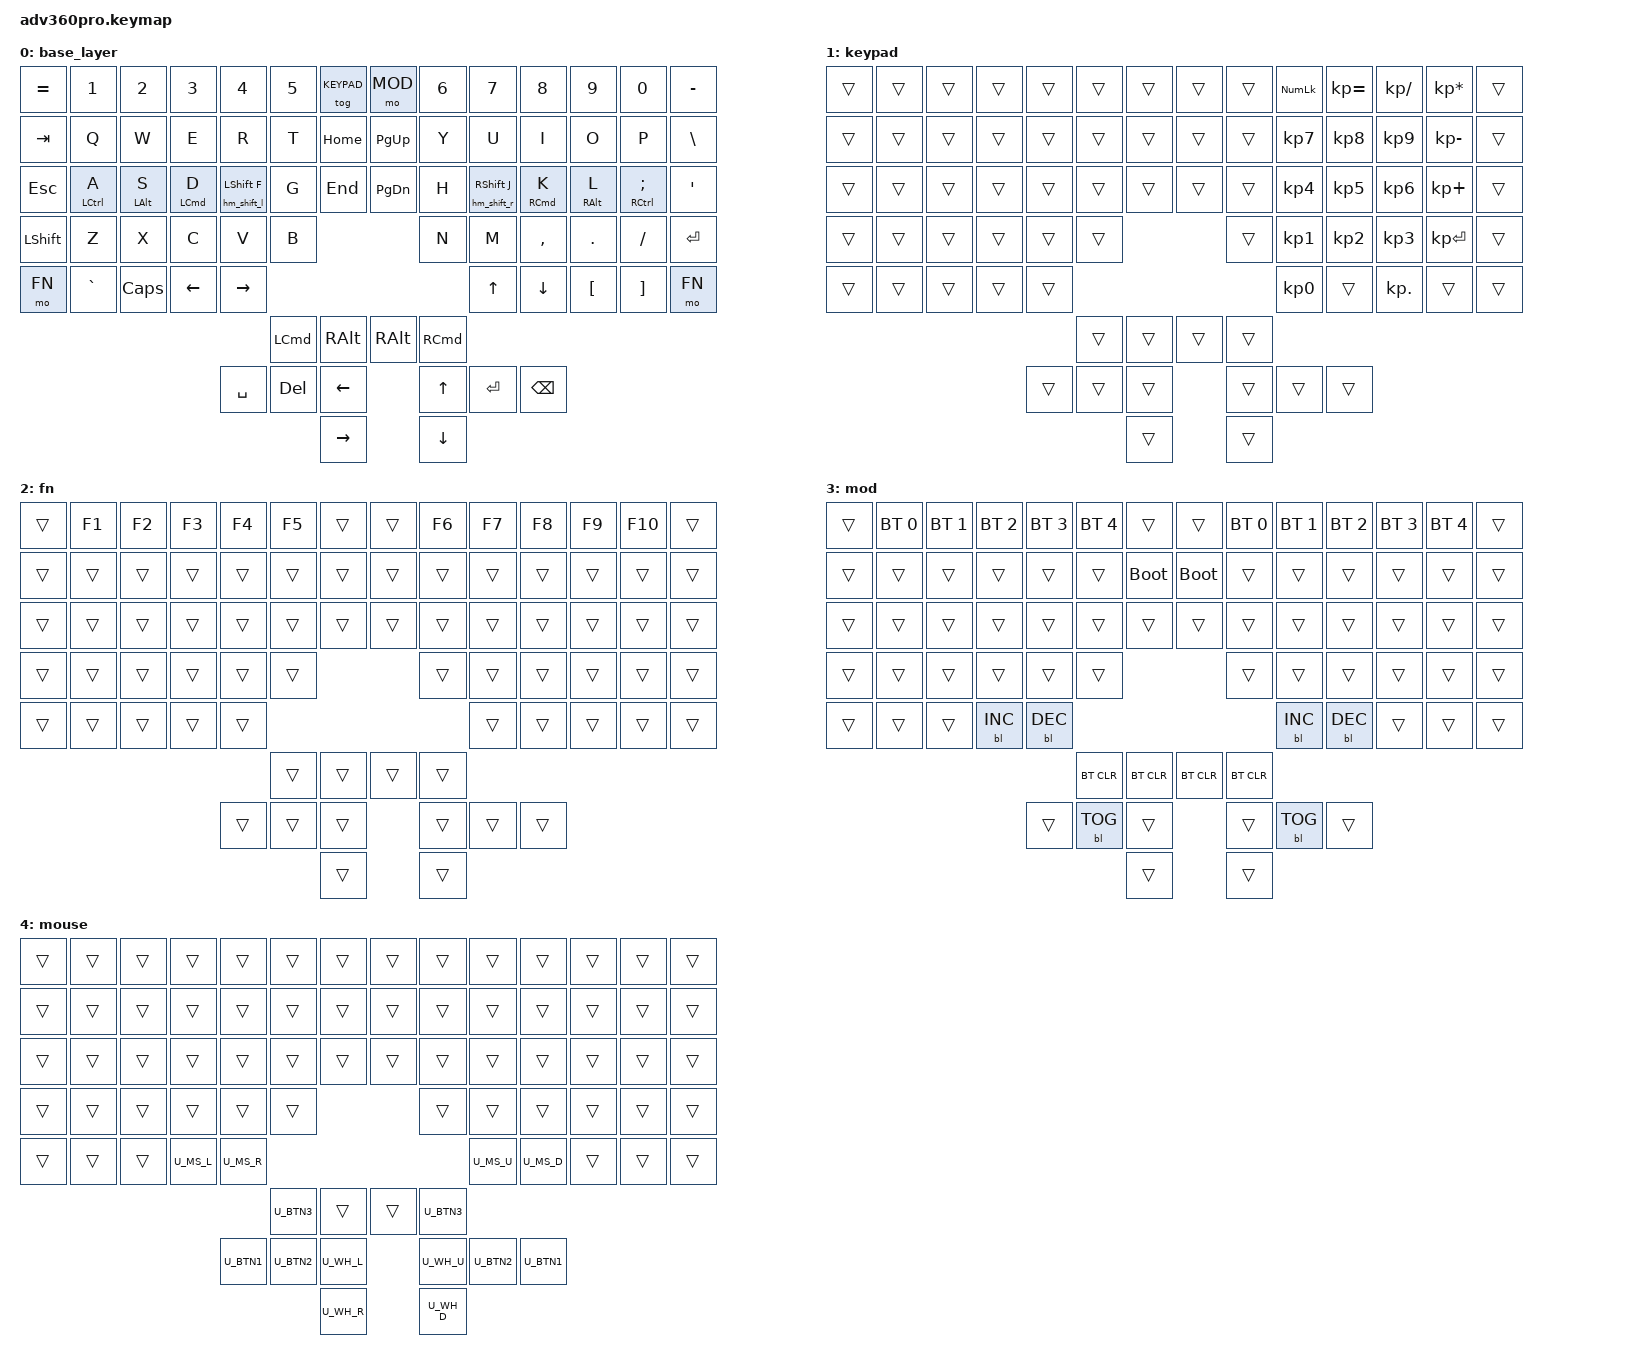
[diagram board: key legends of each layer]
#include <behaviors.dtsi>
#include <dt-bindings/zmk/keys.h>
#include <dt-bindings/zmk/bt.h>
#include <dt-bindings/zmk/outputs.h>
#include <dt-bindings/zmk/rgb.h>
#include <dt-bindings/zmk/backlight.h>

/* definitions for mouse layer */
#include "mouse.dtsi"

#define ___ &trans

#define QWERTY 0
#define KEYPAD 1
#define FN 2
#define MOD 3
#define MS 4


// Personal includes
//#include "includes/settings.dtsi"
#include "includes/behaviours_homerow_mods.dtsi"


/ {
    /* remove unused keys from layout and move thumb cluster to bottom */
    chosen {
        zmk,matrix_transform = &urobs_transform;
    };

    keymap {
        compatible = "zmk,keymap";

        base_layer {
            bindings = <
                &kp EQUAL &kp N1    &kp N2    &kp N3    &kp N4    &kp N5    &tog KEYPAD    &mo MOD   &kp N6    &kp N7    &kp N8    &kp N9    &kp N0    &kp MINUS
                &kp TAB   &kp Q     &kp W     &kp E     &kp R     &kp T     &kp HOME     &kp PG_UP   &kp Y     &kp U     &kp I     &kp O     &kp P     &kp BSLH
                &kp ESC   &hm_l LCTRL A     &hm_l LALT S     &hm_l LCMD D     &hm_shift_l LSHIFT F     &kp G   &kp END    &kp PG_DN     &kp H     &hm_shift_r RSHIFT J     &hm_r RCMD K     &hm_r RALT L     &hm_r RCTRL SEMI  &kp SQT
                &kp LSHFT &kp Z     &kp X     &kp C     &kp V     &kp B                              &kp N     &kp M     &kp COMMA &kp DOT   &kp FSLH  &kp ENTER
                &mo FN    &kp GRAVE &kp CAPS  &kp LEFT  &kp RIGHT                                              &kp UP    &kp DOWN  &kp LBKT  &kp RBKT  &mo FN
                                                                  &kp LCMD &kp RALT       &kp RALT  &kp RCMD
                                                        &kp SPACE  &kp DEL   &kp LEFT_ARROW       &kp UP_ARROW &kp ENTER &kp BSPC
                                                                            &kp RIGHT_ARROW        &kp DOWN_ARROW
            >;
        };

        keypad {
            bindings = <
                ___       ___       ___       ___       ___       ___       ___            ___       ___       &kp KP_NUM &kp KP_EQUAL &kp KP_DIVIDE &kp KP_MULTIPLY ___
                ___       ___       ___       ___       ___       ___       ___            ___       ___       &kp KP_N7  &kp KP_N8    &kp KP_N9     &kp KP_MINUS    ___
                ___       ___       ___       ___       ___       ___       ___            ___       ___       &kp KP_N4  &kp KP_N5    &kp KP_N6     &kp KP_PLUS     ___
                ___       ___       ___       ___       ___       ___                                ___       &kp KP_N1  &kp KP_N2    &kp KP_N3     &kp KP_ENTER    ___
                ___       ___       ___       ___       ___                                                    &kp KP_N0  ___          &kp KP_DOT    ___             ___
                                                                  ___       ___            ___       ___
                                                        ___       ___       ___            ___       ___       ___
                                                                            ___            ___
            >;
        };

        fn {
            bindings = <
                ___       &kp F1    &kp F2    &kp F3    &kp F4    &kp F5    ___            ___       &kp F6    &kp F7    &kp F8    &kp F9    &kp F10   ___
                ___       ___       ___       ___       ___       ___       ___            ___       ___       ___       ___       ___       ___       ___
                ___       ___       ___       ___       ___       ___       ___            ___       ___       ___       ___       ___       ___       ___
                ___       ___       ___       ___       ___       ___                                ___       ___       ___       ___       ___       ___
                ___       ___       ___       ___       ___                                                    ___       ___       ___       ___       ___
                                                                  ___       ___            ___       ___
                                                        ___       ___       ___            ___       ___       ___
                                                                            ___            ___
            >;
        };

        mod {
            bindings = <
                ___       &bt BT_SEL 0 &bt BT_SEL 1 &bt BT_SEL 2 &bt BT_SEL 3 &bt BT_SEL 4 ___              ___         &bt BT_SEL 0 &bt BT_SEL 1     &bt BT_SEL 2 &bt BT_SEL 3 &bt BT_SEL 4 ___
                ___       ___          ___          ___          ___          ___          &bootloader      &bootloader ___          ___              ___          ___          ___          ___
                ___       ___          ___          ___          ___          ___          ___              ___         ___          ___              ___          ___          ___          ___
                ___       ___          ___          ___          ___          ___                                       ___          ___              ___          ___          ___          ___
                ___       ___          ___          &bl BL_INC   &bl BL_DEC                                                          &bl BL_INC       &bl BL_DEC   ___          ___          ___
                                                                              &bt BT_CLR   &bt BT_CLR       &bt BT_CLR  &bt BT_CLR
                                                                 ___          &bl BL_TOG   ___              ___         &bl BL_TOG   ___
                                                                                           ___              ___
            >;
        };

        mouse {
            bindings = <
                ___       ___       ___       ___       ___       ___       ___            ___       ___       ___       ___       ___       ___       ___
                ___       ___       ___       ___       ___       ___       ___            ___       ___       ___       ___       ___       ___       ___
                ___       ___       ___       ___       ___       ___       ___            ___       ___       ___       ___       ___       ___       ___
                ___       ___       ___       ___       ___       ___                                ___       ___       ___       ___       ___       ___
                ___       ___       ___       U_MS_L    U_MS_R                                                 U_MS_U    U_MS_D    ___       ___       ___
                                                                  U_BTN3    ___            ___       U_BTN3
                                                        U_BTN1    U_BTN2    U_WH_L         U_WH_U    U_BTN2    U_BTN1
                                                                            U_WH_R         U_WH_D
            >;
        };

    };

};
